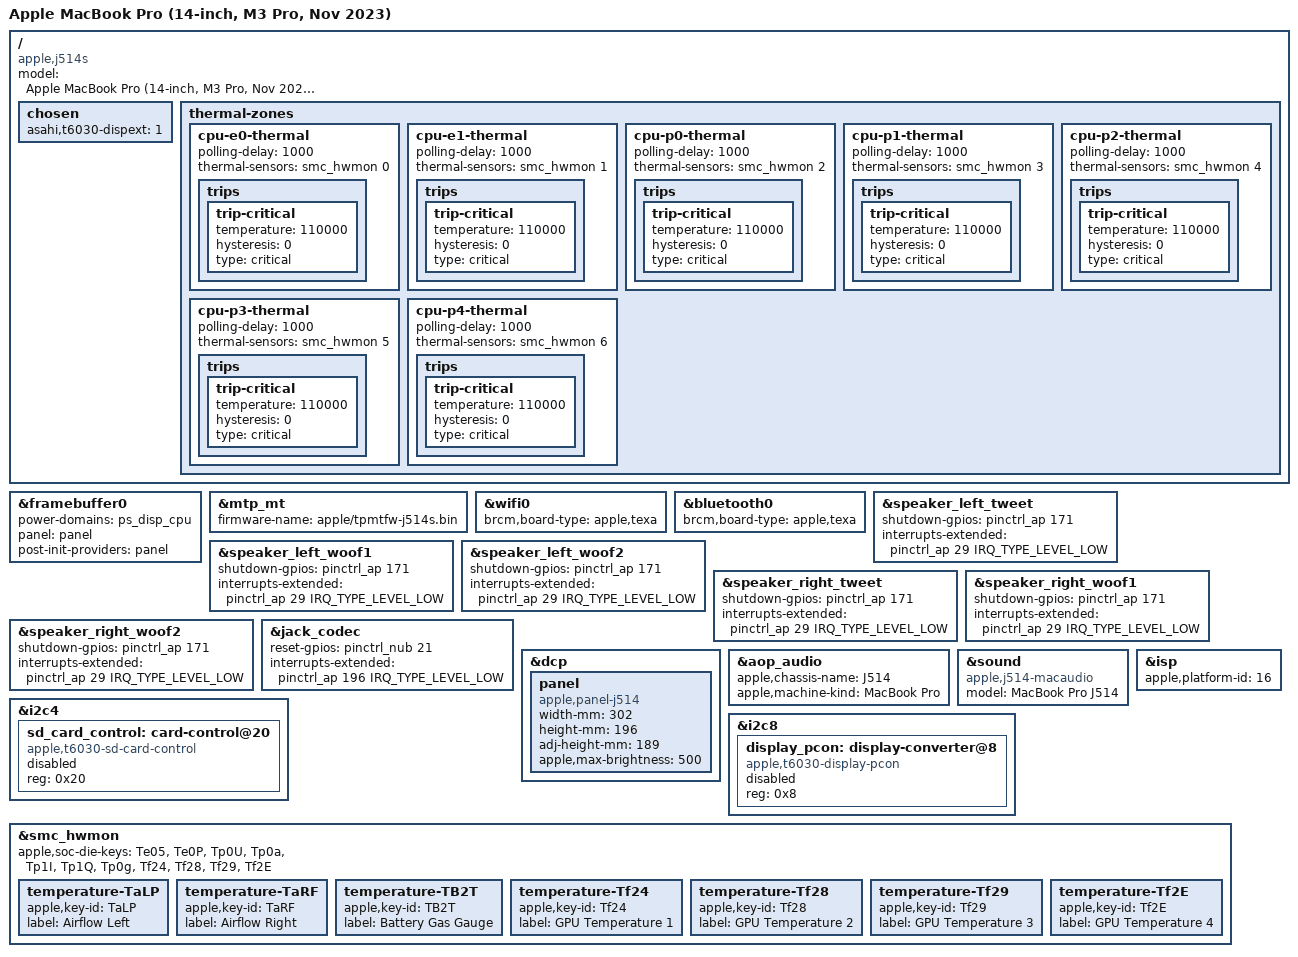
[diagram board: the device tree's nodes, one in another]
// SPDX-License-Identifier: GPL-2.0+ OR MIT
/*
 * MacBook Pro (14-inch, M3 Pro, Nov 2023)
 *
 * target-type: J514s
 *
 * Copyright The Asahi Linux Contributors
 */

/dts-v1/;

#include "t6030.dtsi"
#include "t603x-j514-j516.dtsi"
#include "t603x-j514s-j516s-usb4.dtsi"
#include "t603x-j514s-j516s-hdmi.dtsi"

/ {
	compatible = "apple,j514s", "apple,t6030", "apple,arm-platform";
	model = "Apple MacBook Pro (14-inch, M3 Pro, Nov 2023)";

	chosen {
		asahi,t6030-dispext = "1";
	};

	/*
	 * The SMC runs the fans on its own. Under ten-minute loads (five P
	 * cores, all eleven cores, five P cores plus the GPU) they held the
	 * hottest core sensor at 93-98 C, at up to about 6000 rpm, with no
	 * throttling by Linux. A power allocator throttling below that fought
	 * the fan curve: the fans stayed near 2300 rpm and the P cluster swung
	 * between 696 MHz and 4.06 GHz. So, as on the Qualcomm X1E laptops,
	 * these zones carry only a critical trip, for an orderly shutdown if
	 * the platform's own cooling fails. 110 C matches the J613.
	 */
	thermal-zones {
		cpu-e0-thermal {
			polling-delay = <1000>;
			thermal-sensors = <&smc_hwmon 0>;	/* Te05 */

			trips {
				trip-critical {
					temperature = <110000>;
					hysteresis = <0>;
					type = "critical";
				};
			};
		};

		cpu-e1-thermal {
			polling-delay = <1000>;
			thermal-sensors = <&smc_hwmon 1>;	/* Te0P */

			trips {
				trip-critical {
					temperature = <110000>;
					hysteresis = <0>;
					type = "critical";
				};
			};
		};

		cpu-p0-thermal {
			polling-delay = <1000>;
			thermal-sensors = <&smc_hwmon 2>;	/* Tp0U */

			trips {
				trip-critical {
					temperature = <110000>;
					hysteresis = <0>;
					type = "critical";
				};
			};
		};

		cpu-p1-thermal {
			polling-delay = <1000>;
			thermal-sensors = <&smc_hwmon 3>;	/* Tp0a */

			trips {
				trip-critical {
					temperature = <110000>;
					hysteresis = <0>;
					type = "critical";
				};
			};
		};

		cpu-p2-thermal {
			polling-delay = <1000>;
			thermal-sensors = <&smc_hwmon 4>;	/* Tp1I */

			trips {
				trip-critical {
					temperature = <110000>;
					hysteresis = <0>;
					type = "critical";
				};
			};
		};

		cpu-p3-thermal {
			polling-delay = <1000>;
			thermal-sensors = <&smc_hwmon 5>;	/* Tp1Q */

			trips {
				trip-critical {
					temperature = <110000>;
					hysteresis = <0>;
					type = "critical";
				};
			};
		};

		cpu-p4-thermal {
			polling-delay = <1000>;
			thermal-sensors = <&smc_hwmon 6>;	/* Tp0g */

			trips {
				trip-critical {
					temperature = <110000>;
					hysteresis = <0>;
					type = "critical";
				};
			};
		};
	};
};

&framebuffer0 {
	power-domains = <&ps_disp_cpu>;
	panel = <&panel>;
	post-init-providers = <&panel>;
};

&mtp_mt {
	firmware-name = "apple/tpmtfw-j514s.bin";
};

&wifi0 {
	brcm,board-type = "apple,texa";
};

&bluetooth0 {
	brcm,board-type = "apple,texa";
};

&speaker_left_tweet {
	shutdown-gpios = <&pinctrl_ap 171 GPIO_ACTIVE_HIGH>;
	interrupts-extended = <&pinctrl_ap 29 IRQ_TYPE_LEVEL_LOW>;
};

&speaker_left_woof1 {
	shutdown-gpios = <&pinctrl_ap 171 GPIO_ACTIVE_HIGH>;
	interrupts-extended = <&pinctrl_ap 29 IRQ_TYPE_LEVEL_LOW>;
};

&speaker_left_woof2 {
	shutdown-gpios = <&pinctrl_ap 171 GPIO_ACTIVE_HIGH>;
	interrupts-extended = <&pinctrl_ap 29 IRQ_TYPE_LEVEL_LOW>;
};

&speaker_right_tweet {
	shutdown-gpios = <&pinctrl_ap 171 GPIO_ACTIVE_HIGH>;
	interrupts-extended = <&pinctrl_ap 29 IRQ_TYPE_LEVEL_LOW>;
};

&speaker_right_woof1 {
	shutdown-gpios = <&pinctrl_ap 171 GPIO_ACTIVE_HIGH>;
	interrupts-extended = <&pinctrl_ap 29 IRQ_TYPE_LEVEL_LOW>;
};

&speaker_right_woof2 {
	shutdown-gpios = <&pinctrl_ap 171 GPIO_ACTIVE_HIGH>;
	interrupts-extended = <&pinctrl_ap 29 IRQ_TYPE_LEVEL_LOW>;
};

&jack_codec {
	reset-gpios = <&pinctrl_nub 21 GPIO_ACTIVE_HIGH>;
	interrupts-extended = <&pinctrl_ap 196 IRQ_TYPE_LEVEL_LOW>;
};

&dcp {
	panel: panel {
		compatible = "apple,panel-j514", "apple,panel-mini-led", "apple,panel";
		width-mm = <302>;
		height-mm = <196>;
		adj-height-mm = <189>;
		apple,max-brightness = <500>;
	};
};

&aop_audio {
	apple,chassis-name = "J514";
	apple,machine-kind = "MacBook Pro";
};

&sound {
	compatible = "apple,j514-macaudio", "apple,j314-macaudio", "apple,macaudio";
	model = "MacBook Pro J514";
};

&isp {
	apple,platform-id = <16>;
};

&i2c4 {
	sd_card_control: card-control@20 {
		compatible = "apple,t6030-sd-card-control", "apple,sd-card-control";
		reg = <0x20>;
		status = "disabled";
	};
};

&i2c8 {
	display_pcon: display-converter@8 {
		compatible = "apple,t6030-display-pcon", "apple,display-pcon";
		reg = <0x8>;
		status = "disabled";
	};
};

/*
 * The SoC die keys of this machine, in place of the T6030 list: the CPU
 * die keys of its temperature channels (two for the E cluster, one per P
 * core), plus the four Tf2x keys that rose 11-14 C with only the GPU busy
 * and about 1 C with all P cores busy. The GPU's own Tg keys read 0 C or
 * slightly below on this machine even with the GPU rendering, so they are
 * not used. Tf2D also follows the GPU but swings by more than 10 C with no
 * GPU load, and is left out.
 */
&smc_hwmon {
	apple,soc-die-keys = "Te05", "Te0P", "Tp0U", "Tp0a", "Tp1I", "Tp1Q",
			     "Tp0g", "Tf24", "Tf28", "Tf29", "Tf2E";
};

/*
 * Further SMC temperature keys of this machine. TB2T reads what macOS
 * shows as the battery gas gauge's temperature (TB1T repeats TB0T). The
 * four Tf2x keys follow the GPU: on macOS they track its Tg keys about
 * 8 C below them, and here they rose 11-14 C with only the GPU busy and
 * about 1 C with all P cores busy. The Tg keys read 0 C under Linux.
 */
&smc_hwmon {
	temperature-TaLP {
		apple,key-id = "TaLP";
		label = "Airflow Left";
	};

	temperature-TaRF {
		apple,key-id = "TaRF";
		label = "Airflow Right";
	};

	temperature-TB2T {
		apple,key-id = "TB2T";
		label = "Battery Gas Gauge";
	};

	temperature-Tf24 {
		apple,key-id = "Tf24";
		label = "GPU Temperature 1";
	};

	temperature-Tf28 {
		apple,key-id = "Tf28";
		label = "GPU Temperature 2";
	};

	temperature-Tf29 {
		apple,key-id = "Tf29";
		label = "GPU Temperature 3";
	};

	temperature-Tf2E {
		apple,key-id = "Tf2E";
		label = "GPU Temperature 4";
	};
};
